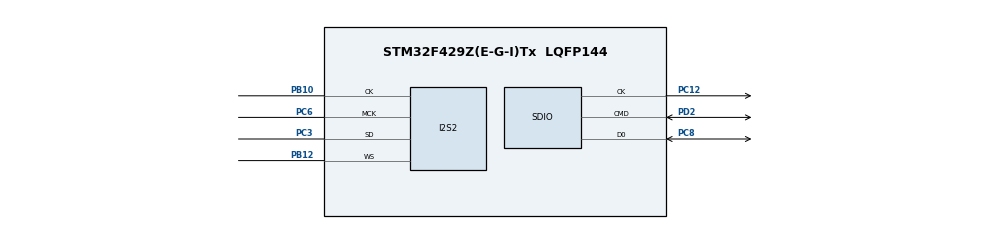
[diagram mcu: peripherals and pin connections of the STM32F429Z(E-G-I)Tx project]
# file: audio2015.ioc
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Dma.Request0=SPI2_TX
Dma.SPI2_TX.0.Channel=DMA_CHANNEL_0
Dma.SPI2_TX.0.Direction=DMA_MEMORY_TO_PERIPH
Dma.SPI2_TX.0.FIFOMode=DMA_FIFOMODE_DISABLE
Dma.SPI2_TX.0.Instance=DMA1_Stream4
Dma.SPI2_TX.0.MemDataAlignment=DMA_MDATAALIGN_HALFWORD
Dma.SPI2_TX.0.MemInc=DMA_MINC_ENABLE
Dma.SPI2_TX.0.Mode=DMA_NORMAL
Dma.SPI2_TX.0.PeriphDataAlignment=DMA_PDATAALIGN_HALFWORD
Dma.SPI2_TX.0.PeriphInc=DMA_PINC_DISABLE
Dma.SPI2_TX.0.Priority=DMA_PRIORITY_MEDIUM
I2S2.AudioFreq=I2S_AUDIOFREQ_44K
I2S2.ErrorAudioFreq=-5.3 %
I2S2.RealAudioFreq=41.666 KHz
Mcu.Family=STM32F4
Mcu.Name=STM32F429Z(E-G-I)Tx
Mcu.Package=LQFP144
NVIC.DMA1_Stream4_IRQn=true\:0\:0\:false
NVIC.PriorityGroup=NVIC_PRIORITYGROUP_4
PA13.Mode=Serial-Wire
PA13.Signal=SYS_JTMS-SWDIO
PA14.Mode=Serial-Wire
PA14.Signal=SYS_JTCK-SWCLK
PA4.Signal=I2S3_WS
PB10.Mode=Half_Duplex_Master
PB10.Signal=I2S2_CK
PB12.Mode=Half_Duplex_Master
PB12.Signal=I2S2_WS
PC12.Mode=SD_1_bit
PC12.Signal=SDIO_CK
PC3.Mode=Half_Duplex_Master
PC3.Signal=I2S2_SD
PC6.Mode=Master_Clock_Activated
PC6.Signal=I2S2_MCK
PC8.Mode=SD_1_bit
PC8.Signal=SDIO_D0
PD2.Mode=SD_1_bit
PD2.Signal=SDIO_CMD
ProjectManager.TargetToolchain=MDK-ARM V5
RCC.48MHZClocksFreq_Value=38400000
RCC.AHBFreq_Value=16000000
RCC.APB1Freq_Value=16000000
RCC.APB1TimFreq_Value=16000000
RCC.APB2Freq_Value=16000000
RCC.APB2TimFreq_Value=16000000
RCC.CortexFreq_Value=16000000
RCC.HCLKFreq_Value=16000000
RCC.HSE_VALUE=25000000
RCC.HSI_VALUE=16000000
RCC.LSE_VALUE=32768
RCC.PLLI2SN=120
RCC.PLLM=15
RCC.PLLN=144
RCC.SYSCLKFreq_VALUE=16000000
RCC.VCOOutputFreq_Value=153600000
SDIO.BusWide=SDIO_BUS_WIDE_1B
VP_FATFS_VS_SDIO.Mode=SDIO
board=audio2015

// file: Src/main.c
/**
  ******************************************************************************
  * File Name          : main.c
  * Description        : Main program body
  ******************************************************************************
  *
  * COPYRIGHT(c) 2016 STMicroelectronics
  *
  * Redistribution and use in source and binary forms, with or without modification,
  * are permitted provided that the following conditions are met:
  *   1. Redistributions of source code must retain the above copyright notice,
  *      this list of conditions and the following disclaimer.
  *   2. Redistributions in binary form must reproduce the above copyright notice,
  *      this list of conditions and the following disclaimer in the documentation
  *      and/or other materials provided with the distribution.
  *   3. Neither the name of STMicroelectronics nor the names of its contributors
  *      may be used to endorse or promote products derived from this software
  *      without specific prior written permission.
  *
  * THIS SOFTWARE IS PROVIDED BY THE COPYRIGHT HOLDERS AND CONTRIBUTORS "AS IS"
  * AND ANY EXPRESS OR IMPLIED WARRANTIES, INCLUDING, BUT NOT LIMITED TO, THE
  * IMPLIED WARRANTIES OF MERCHANTABILITY AND FITNESS FOR A PARTICULAR PURPOSE ARE
  * DISCLAIMED. IN NO EVENT SHALL THE COPYRIGHT HOLDER OR CONTRIBUTORS BE LIABLE
  * FOR ANY DIRECT, INDIRECT, INCIDENTAL, SPECIAL, EXEMPLARY, OR CONSEQUENTIAL
  * DAMAGES (INCLUDING, BUT NOT LIMITED TO, PROCUREMENT OF SUBSTITUTE GOODS OR
  * SERVICES; LOSS OF USE, DATA, OR PROFITS; OR BUSINESS INTERRUPTION) HOWEVER
  * CAUSED AND ON ANY THEORY OF LIABILITY, WHETHER IN CONTRACT, STRICT LIABILITY,
  * OR TORT (INCLUDING NEGLIGENCE OR OTHERWISE) ARISING IN ANY WAY OUT OF THE USE
  * OF THIS SOFTWARE, EVEN IF ADVISED OF THE POSSIBILITY OF SUCH DAMAGE.
  *
  ******************************************************************************
  */
#include "stm32f4xx_hal.h"
#include "fatfs.h"

/* USER CODE BEGIN Includes */
#include "debug.h"
#include "waveplayer.h"
/* USER CODE END Includes */

I2S_HandleTypeDef hi2s2;
DMA_HandleTypeDef hdma_spi2_tx;

SD_HandleTypeDef hsd;
HAL_SD_CardInfoTypedef SDCardInfo;

/* USER CODE BEGIN PV */
/* Private variables ---------------------------------------------------------*/
extern uint8_t retSD;    /* Return value for SD */
extern char SD_Path[4];  /* SD logical drive path */
FATFS fatfs;
int res;
HAL_SD_CardInfoTypedef SDInfo;
int playindex=1;
/* USER CODE END PV */

void SystemClock_Config(void);
static void MX_GPIO_Init(void);
static void MX_DMA_Init(void);
static void MX_I2S2_Init(void);
static void MX_SDIO_SD_Init(void);

/* USER CODE BEGIN PFP */
/* Private function prototypes -----------------------------------------------*/

/* USER CODE END PFP */

int main(void)
{

  /* MCU Configuration----------------------------------------------------------*/

  /* Reset of all peripherals, Initializes the Flash interface and the Systick. */
  HAL_Init();

  /* Configure the system clock */
  SystemClock_Config();

  /* Initialize all configured peripherals */
  MX_GPIO_Init();
  MX_DMA_Init();
  MX_I2S2_Init();
  MX_SDIO_SD_Init();
  MX_FATFS_Init();

  /* USER CODE BEGIN 2 */
	printf("Init complete");
	//WavePlayerStartSample();
	while((res=f_mount (&fatfs, SD_Path, 1))!=FR_OK)
	{
		printf("QQ");
	}
	WavePlayerStart_DMA("0:/akuno.wav");
	//playindex=rand()%6;
	/*switch(playindex)
	{
		case :
			WavePlayerStart_DMA("0:/test.wav");
			break;
		case 1:
			WavePlayerStart_DMA("0:/akuno.wav");
			break;
		default:
			WavePlayerStart_DMA("0:/akuno.wav");
			break;
	}*/
  /* USER CODE END 2 */

  /* Infinite loop */
  while (1)
  {

  /* USER CODE BEGIN 3 */
		//WavePlayerStart_DMA("0:/test.wav");
  }
  /* USER CODE END 3 */

}

/** System Clock Configuration
*/
void SystemClock_Config(void)
{

  RCC_OscInitTypeDef RCC_OscInitStruct;
  RCC_PeriphCLKInitTypeDef PeriphClkInitStruct;

  __PWR_CLK_ENABLE();

  __HAL_PWR_VOLTAGESCALING_CONFIG(PWR_REGULATOR_VOLTAGE_SCALE3);

  RCC_OscInitStruct.OscillatorType = RCC_OSCILLATORTYPE_HSI;
  RCC_OscInitStruct.HSIState = RCC_HSI_ON;
  RCC_OscInitStruct.HSICalibrationValue = 16;
  RCC_OscInitStruct.PLL.PLLState = RCC_PLL_ON;
  RCC_OscInitStruct.PLL.PLLSource = RCC_PLLSOURCE_HSI;
  RCC_OscInitStruct.PLL.PLLM = 15;
  RCC_OscInitStruct.PLL.PLLN = 144;
  RCC_OscInitStruct.PLL.PLLP = RCC_PLLP_DIV2;
  RCC_OscInitStruct.PLL.PLLQ = 4;
  HAL_RCC_OscConfig(&RCC_OscInitStruct);

  PeriphClkInitStruct.PeriphClockSelection = RCC_PERIPHCLK_I2S;
  PeriphClkInitStruct.PLLI2S.PLLI2SN = 120;
  PeriphClkInitStruct.PLLI2S.PLLI2SR = 2;
  HAL_RCCEx_PeriphCLKConfig(&PeriphClkInitStruct);

  HAL_SYSTICK_Config(HAL_RCC_GetHCLKFreq()/1000);

  HAL_SYSTICK_CLKSourceConfig(SYSTICK_CLKSOURCE_HCLK);

  /* SysTick_IRQn interrupt configuration */
  HAL_NVIC_SetPriority(SysTick_IRQn, 0, 0);
}

/* I2S2 init function */
void MX_I2S2_Init(void)
{

  hi2s2.Instance = SPI2;
  hi2s2.Init.Mode = I2S_MODE_MASTER_TX;
  hi2s2.Init.Standard = I2S_STANDARD_PHILLIPS;
  hi2s2.Init.DataFormat = I2S_DATAFORMAT_16B;
  hi2s2.Init.MCLKOutput = I2S_MCLKOUTPUT_ENABLE;
  hi2s2.Init.AudioFreq = I2S_AUDIOFREQ_44K;
  hi2s2.Init.CPOL = I2S_CPOL_LOW;
  hi2s2.Init.ClockSource = I2S_CLOCK_PLL;
  hi2s2.Init.FullDuplexMode = I2S_FULLDUPLEXMODE_DISABLE;
  HAL_I2S_Init(&hi2s2);

}

/* SDIO init function */
void MX_SDIO_SD_Init(void)
{

  hsd.Instance = SDIO;
  hsd.Init.ClockEdge = SDIO_CLOCK_EDGE_RISING;
  hsd.Init.ClockBypass = SDIO_CLOCK_BYPASS_DISABLE;
  hsd.Init.ClockPowerSave = SDIO_CLOCK_POWER_SAVE_DISABLE;
  hsd.Init.BusWide = SDIO_BUS_WIDE_1B;
  hsd.Init.HardwareFlowControl = SDIO_HARDWARE_FLOW_CONTROL_DISABLE;
  hsd.Init.ClockDiv = 0;

}

void MX_DMA_Init(void)
{
  /* DMA controller clock enable */
  __DMA1_CLK_ENABLE();

  /* DMA interrupt init */
  HAL_NVIC_SetPriority(DMA1_Stream4_IRQn, 0, 0);
  HAL_NVIC_EnableIRQ(DMA1_Stream4_IRQn);

}

/** Configure pins
     PA4   ------> I2S3_WS
*/
void MX_GPIO_Init(void)
{

  GPIO_InitTypeDef GPIO_InitStruct;

  /* GPIO Ports Clock Enable */
  __GPIOC_CLK_ENABLE();
  __GPIOA_CLK_ENABLE();
  __GPIOB_CLK_ENABLE();
  __GPIOD_CLK_ENABLE();

  /*Configure GPIO pin : PA4 */
  GPIO_InitStruct.Pin = GPIO_PIN_4;
  GPIO_InitStruct.Mode = GPIO_MODE_AF_PP;
  GPIO_InitStruct.Pull = GPIO_NOPULL;
  GPIO_InitStruct.Speed = GPIO_SPEED_LOW;
  GPIO_InitStruct.Alternate = GPIO_AF6_SPI3;
  HAL_GPIO_Init(GPIOA, &GPIO_InitStruct);

}

/* USER CODE BEGIN 4 */
	//HAL_SD_Init(&hsd, &SDInfo);
/* USER CODE END 4 */

/************************ (C) COPYRIGHT STMicroelectronics *****END OF FILE****/
